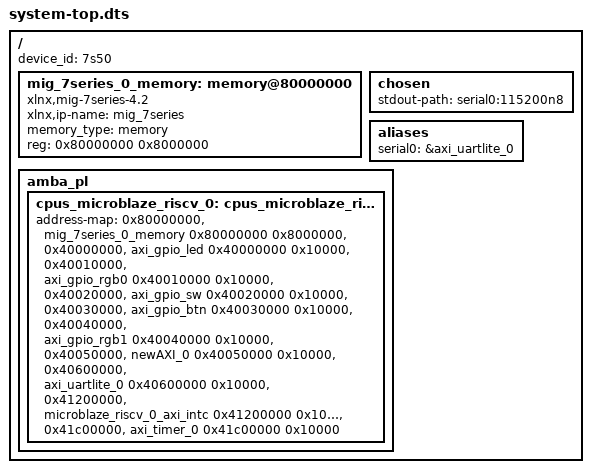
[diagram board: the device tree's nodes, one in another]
/dts-v1/;
#include "pl.dtsi"
/ {
	device_id = "7s50";
	#address-cells = <1>;
	#size-cells = <1>;
	mig_7series_0_memory: memory@80000000 {
		compatible = "xlnx,mig-7series-4.2";
		xlnx,ip-name = "mig_7series";
		device_type = "memory";
		memory_type = "memory";
		reg = <0x80000000 0x8000000>;
	};
	chosen {
		stdout-path = "serial0:115200n8";
	};
	aliases {
		serial0 = &axi_uartlite_0;
	};
	amba_pl: amba_pl {
		cpus_microblaze_riscv_0: cpus_microblaze_riscv@0 {
			address-map = <0x80000000 &mig_7series_0_memory 0x80000000 0x8000000>, 
			      <0x40000000 &axi_gpio_led 0x40000000 0x10000>, 
			      <0x40010000 &axi_gpio_rgb0 0x40010000 0x10000>, 
			      <0x40020000 &axi_gpio_sw 0x40020000 0x10000>, 
			      <0x40030000 &axi_gpio_btn 0x40030000 0x10000>, 
			      <0x40040000 &axi_gpio_rgb1 0x40040000 0x10000>, 
			      <0x40050000 &newAXI_0 0x40050000 0x10000>, 
			      <0x40600000 &axi_uartlite_0 0x40600000 0x10000>, 
			      <0x41200000 &microblaze_riscv_0_axi_intc 0x41200000 0x10000>, 
			      <0x41c00000 &axi_timer_0 0x41c00000 0x10000>;
			#ranges-address-cells = <0x1>;
			#ranges-size-cells = <0x1>;
		};
	};
};
